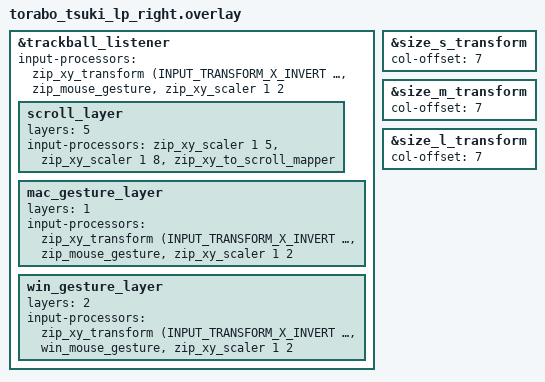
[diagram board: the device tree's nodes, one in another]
#include "torabo_tsuki_lp.dtsi"
#include <input/processors.dtsi>
#include <dt-bindings/zmk/input_transform.h>

&trackball_listener {
    // 1596 CPIを1/2にして、実効約800 CPIにする。
    input-processors = <&zip_xy_transform (INPUT_TRANSFORM_X_INVERT | INPUT_TRANSFORM_Y_INVERT)
                        &zip_mouse_gesture
                        &zip_xy_scaler 1 2>;
    
    scroll_layer: scroll_layer {
        layers = <5>;
        // 1596 CPI / 40で、798 CPI / 20と同じ実効速度にする。
        // ZMK推奨の係数上限16に収めるため、1/5と1/8の二段に分ける。
        input-processors = <&zip_xy_scaler 1 5
                            &zip_xy_scaler 1 8
                            &zip_xy_to_scroll_mapper>;
    };

    mac_gesture_layer: mac_gesture_layer {
        layers = <1>;
        input-processors = <&zip_xy_transform (INPUT_TRANSFORM_X_INVERT | INPUT_TRANSFORM_Y_INVERT)
                            &zip_mouse_gesture
                            &zip_xy_scaler 1 2>;
    };

    win_gesture_layer: win_gesture_layer {
        layers = <2>;
        // Windowsも実効約800 CPIとし、前回より追従を約20%上げる。
        input-processors = <&zip_xy_transform (INPUT_TRANSFORM_X_INVERT | INPUT_TRANSFORM_Y_INVERT)
                            &win_mouse_gesture
                            &zip_xy_scaler 1 2>;
    };
};

&size_s_transform {
    col-offset = <7>;
};

&size_m_transform {
    col-offset = <7>;
};

&size_l_transform {
    col-offset = <7>;
};
